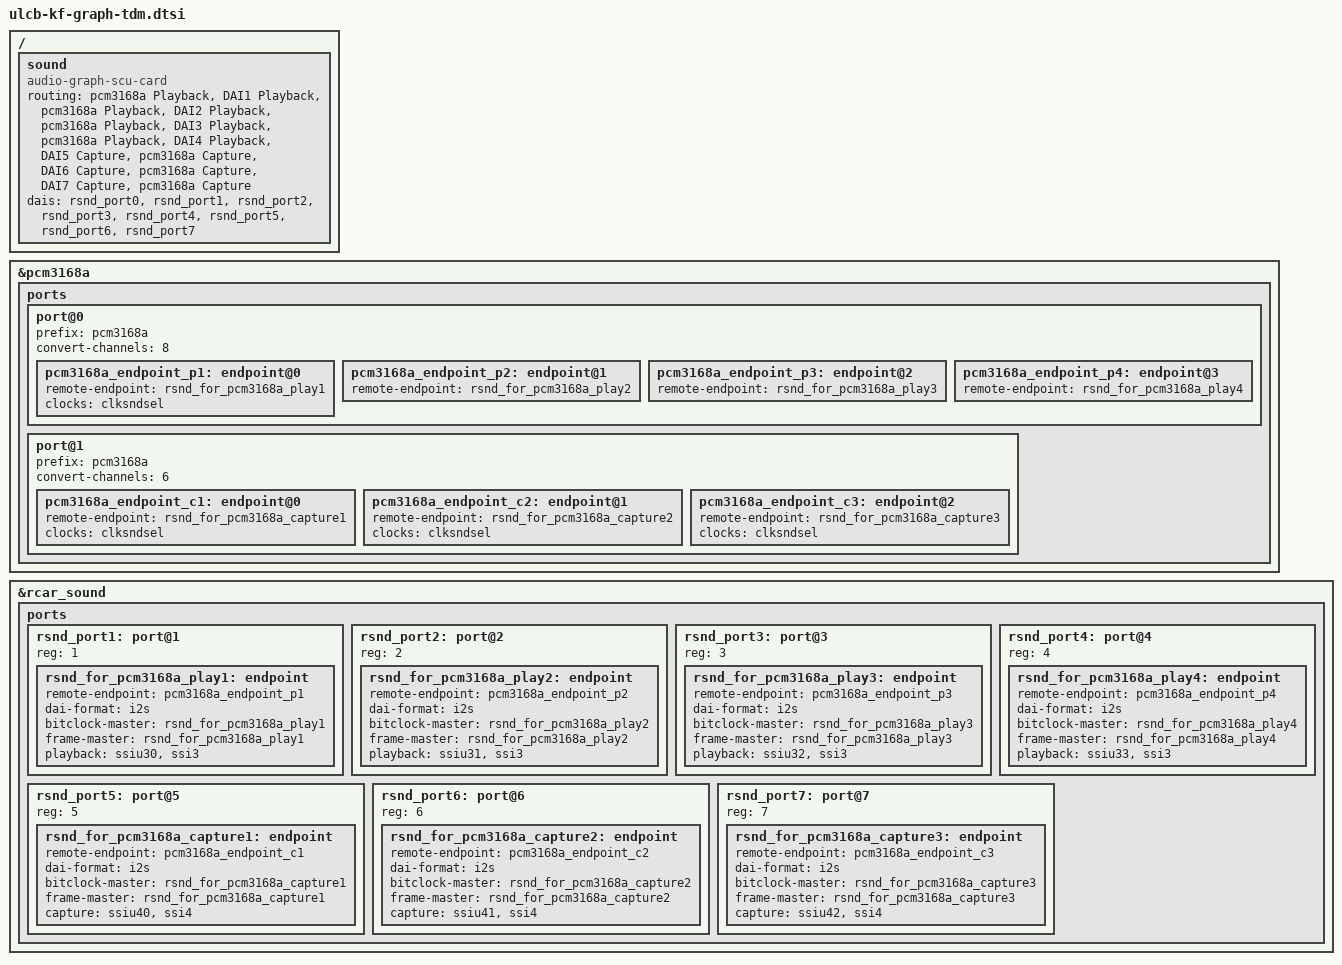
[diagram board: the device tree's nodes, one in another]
/*
 * Current ULCB-KF sound is using Audio-Graph
 *
 *	CPU0 ------ ak4613
 *	CPU1 ------ HDMI
 *	CPU2 ------ PCM3168A-p
 *	CPU3 ------ PCM3168A-c
 *
 * This patch uses TDM Split
 *
 *	CPU0 ------ ak4613
 *	CPU1 ------ PCM3168A-p	// 1ch/2ch
 *	CPU2 --/		// 3ch/4ch
 *	CPU3 --/		// 5ch/6ch
 *	CPU4 --/		// 7ch/8ch
 *	CPU5 ------ PCM3168A-c	// 1ch/2ch
 *	CPU6 --/		// 3ch/4ch
 *	CPU7 --/		// 5ch/6ch
 *
 *	aplay   -D plughw:0,0 xxx.wav // ak4613
 *	aplay   -D plughw:0,1 xxx.wav // PCM3168A playback 1ch/2ch
 *	aplay   -D plughw:0,2 xxx.wav // PCM3168A playback 3ch/4ch
 *	aplay   -D plughw:0,3 xxx.wav // PCM3168A playback 5ch/6ch
 *	aplay   -D plughw:0,4 xxx.wav // PCM3168A playback 7ch/8ch
 *	arecord -D plughw:0,5 xxx     // PCM8168A capture  1ch/2ch
 *	arecord -D plughw:0,6 xxx     // PCM8168A capture  3ch/4ch
 *	arecord -D plughw:0,7 xxx     // PCM8168A capture  5ch/6ch
 */
/delete-node/ &sound_card;
/delete-node/ &rsnd_for_pcm3168a_play;
/delete-node/ &rsnd_for_pcm3168a_capture;
/delete-node/ &pcm3168a_endpoint_p;
/delete-node/ &pcm3168a_endpoint_c;
/delete-node/ &rsnd_port1;
/delete-node/ &rsnd_port2;
/delete-node/ &rsnd_port3;
/delete-node/ &dw_hdmi0_snd_in;

/ {
	sound {
		compatible = "audio-graph-scu-card";

		routing =	"pcm3168a Playback", "DAI1 Playback",
				"pcm3168a Playback", "DAI2 Playback",
				"pcm3168a Playback", "DAI3 Playback",
				"pcm3168a Playback", "DAI4 Playback",
				"DAI5 Capture", "pcm3168a Capture",
				"DAI6 Capture", "pcm3168a Capture",
				"DAI7 Capture", "pcm3168a Capture";

		dais =	<&rsnd_port0 /* ak4613 */
			 &rsnd_port1 /* pcm3168a playback 1ch/2ch */
			 &rsnd_port2 /*			  3ch/4ch */
			 &rsnd_port3 /*			  5ch/6ch */
			 &rsnd_port4 /*			  7ch/8ch */
			 &rsnd_port5 /* pcm3168a capture  1ch/2ch */
			 &rsnd_port6 /*			  3ch/4ch */
			 &rsnd_port7 /*			  5ch/6ch */
		>;
	};
};

&pcm3168a {
	#sound-dai-cells = <1>;

	ports {
		port@0 {
			prefix = "pcm3168a";
			convert-channels = <8>; /* TDM Split */
			pcm3168a_endpoint_p1: endpoint@0 {
				remote-endpoint = <&rsnd_for_pcm3168a_play1>;
				clocks = <&clksndsel>;
			};
			pcm3168a_endpoint_p2: endpoint@1 {
				remote-endpoint = <&rsnd_for_pcm3168a_play2>;
			};
			pcm3168a_endpoint_p3: endpoint@2 {
				remote-endpoint = <&rsnd_for_pcm3168a_play3>;
			};
			pcm3168a_endpoint_p4: endpoint@3 {
				remote-endpoint = <&rsnd_for_pcm3168a_play4>;
			};
		};
		 port@1 {
			prefix = "pcm3168a";
			convert-channels = <6>; /* TDM Split */
			pcm3168a_endpoint_c1: endpoint@0 {
				remote-endpoint = <&rsnd_for_pcm3168a_capture1>;
				clocks = <&clksndsel>;
			};
			pcm3168a_endpoint_c2: endpoint@1 {
				remote-endpoint = <&rsnd_for_pcm3168a_capture2>;
				clocks = <&clksndsel>;
			};
			pcm3168a_endpoint_c3: endpoint@2 {
				remote-endpoint = <&rsnd_for_pcm3168a_capture3>;
				clocks = <&clksndsel>;
			};
		};
	};
};

&rcar_sound {
	#sound-dai-cells = <1>;

	ports {
		/* rsnd_port0 is on salvator-common */
		rsnd_port1: port@1 {
			reg = <1>;
			rsnd_for_pcm3168a_play1: endpoint {
				remote-endpoint = <&pcm3168a_endpoint_p1>;
				dai-format = "i2s";
				bitclock-master = <&rsnd_for_pcm3168a_play1>;
				frame-master    = <&rsnd_for_pcm3168a_play1>;
				playback = <&ssiu30 &ssi3>;
			};
		};
		rsnd_port2: port@2 {
			reg = <2>;
			rsnd_for_pcm3168a_play2: endpoint {
				remote-endpoint = <&pcm3168a_endpoint_p2>;
				dai-format = "i2s";
				bitclock-master = <&rsnd_for_pcm3168a_play2>;
				frame-master    = <&rsnd_for_pcm3168a_play2>;
				playback = <&ssiu31 &ssi3>;
			};
		};
		rsnd_port3: port@3 {
			reg = <3>;
			rsnd_for_pcm3168a_play3: endpoint {
				remote-endpoint = <&pcm3168a_endpoint_p3>;
				dai-format = "i2s";
				bitclock-master = <&rsnd_for_pcm3168a_play3>;
				frame-master    = <&rsnd_for_pcm3168a_play3>;
				playback = <&ssiu32 &ssi3>;
			};
		};
		rsnd_port4: port@4 {
			reg = <4>;
			rsnd_for_pcm3168a_play4: endpoint {
				remote-endpoint = <&pcm3168a_endpoint_p4>;
				dai-format = "i2s";
				bitclock-master = <&rsnd_for_pcm3168a_play4>;
				frame-master    = <&rsnd_for_pcm3168a_play4>;
				playback = <&ssiu33 &ssi3>;
			};
		};
		rsnd_port5: port@5 {
			reg = <5>;
			rsnd_for_pcm3168a_capture1: endpoint {
				remote-endpoint = <&pcm3168a_endpoint_c1>;
				dai-format = "i2s";
				bitclock-master = <&rsnd_for_pcm3168a_capture1>;
				frame-master    = <&rsnd_for_pcm3168a_capture1>;
				capture  = <&ssiu40 &ssi4>;
			};
		};
		rsnd_port6: port@6 {
			reg = <6>;
			rsnd_for_pcm3168a_capture2: endpoint {
				remote-endpoint = <&pcm3168a_endpoint_c2>;
				dai-format = "i2s";
				bitclock-master = <&rsnd_for_pcm3168a_capture2>;
				frame-master    = <&rsnd_for_pcm3168a_capture2>;
				capture  = <&ssiu41 &ssi4>;
			};
		};
		rsnd_port7: port@7 {
			reg = <7>;
			rsnd_for_pcm3168a_capture3: endpoint {
				remote-endpoint = <&pcm3168a_endpoint_c3>;
				dai-format = "i2s";
				bitclock-master = <&rsnd_for_pcm3168a_capture3>;
				frame-master    = <&rsnd_for_pcm3168a_capture3>;
				capture  = <&ssiu42 &ssi4>;
			};
		};
	};
};
